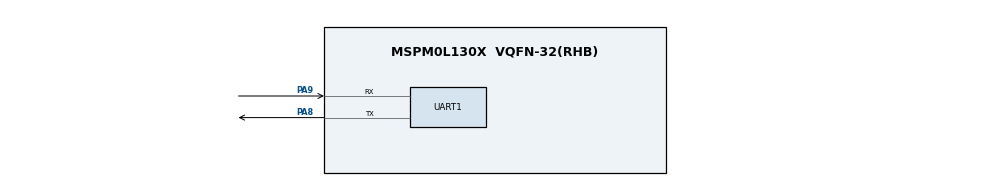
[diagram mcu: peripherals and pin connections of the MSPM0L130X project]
// @cliArgs --device "MSPM0L130X" --package "VQFN-32(RHB)" --part "Default"
// @cliArgs --board /ti/boards/LP_MSPM0L1306 --rtos nortos

/**
 * Import the modules used in this configuration.
 */
const GPIO   = scripting.addModule("/ti/driverlib/GPIO", {}, false);
const GPIO1  = GPIO.addInstance();
const SYSCTL = scripting.addModule("/ti/driverlib/SYSCTL");
const UART   = scripting.addModule("/ti/driverlib/UART", {}, false);
const UART1  = UART.addInstance();

/**
 * Write custom configuration values to the imported modules.
 */
GPIO1.$name                          = "GPIO_LEDS";
GPIO1.associatedPins.create(2);
GPIO1.associatedPins[0].$name        = "USER_LED_1";
GPIO1.associatedPins[0].assignedPort = "PORTA";
GPIO1.associatedPins[0].assignedPin  = "0";
GPIO1.associatedPins[0].initialValue = "SET";
GPIO1.associatedPins[1].$name        = "USER_TEST";
GPIO1.associatedPins[1].initialValue = "SET";
GPIO1.associatedPins[1].assignedPort = "PORTA";
GPIO1.associatedPins[1].assignedPin  = "1";

const Board = scripting.addModule("/ti/driverlib/Board", {}, false);

SYSCTL.clockTreeEn = true;

UART1.$name                    = "UART_0";
UART1.enableFIFO               = true;
UART1.enableDMARX              = false;
UART1.enableDMATX              = false;
UART1.targetBaudRate           = 9600;
UART1.enableInternalLoopback   = false;
UART1.rxFifoThreshold          = "DL_UART_RX_FIFO_LEVEL_1_2_FULL";
UART1.peripheral.$assign       = "UART0";
UART1.peripheral.rxPin.$assign = "PA9";
UART1.peripheral.txPin.$assign = "PA8";
